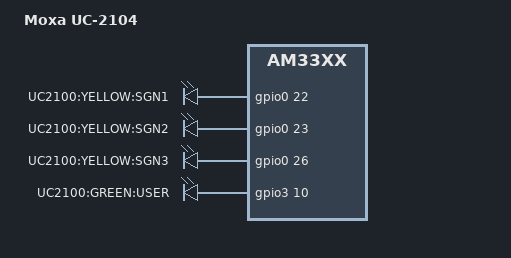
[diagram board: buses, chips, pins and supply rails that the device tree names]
/*
 * Copyright (C) 2018 MOXA Inc. - https://www.moxa.com/
 *
 * Authors: SZ Lin (林上智) <sz.lin@moxa.com>
 *          Wes Huang (黃淵河) <wes.huang@moxa.com>
 *          Fero JD Zhou (周俊達) <FeroJD.Zhou@moxa.com>
 *
 */

#include "am335x-moxa-uc-2101.dts"

/ {
	model = "Moxa UC-2104";
	compatible = "moxa,uc-2104", "ti,am33xx";

	leds {
		compatible = "gpio-leds";
		led1 {
			label = "UC2100:YELLOW:SGN1";
			gpios = <&gpio0 22 GPIO_ACTIVE_HIGH>;
			default-state = "off";
		};

		led2 {
			label = "UC2100:YELLOW:SGN2";
			gpios = <&gpio0 23 GPIO_ACTIVE_HIGH>;
			default-state = "off";
		};

		led3 {
			label = "UC2100:YELLOW:SGN3";
			gpios = <&gpio0 26 GPIO_ACTIVE_HIGH>;
			default-state = "off";
		};

		led4 {
			label = "UC2100:GREEN:USER";
			gpios = <&gpio3 10 GPIO_ACTIVE_HIGH>;
			default-state = "off";
		};
	};
};
